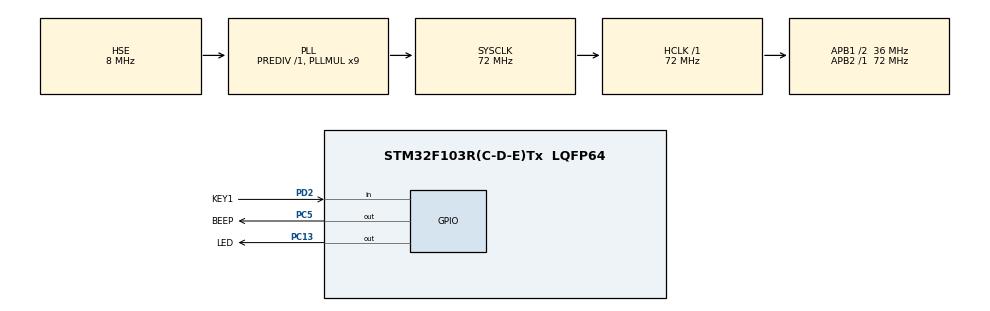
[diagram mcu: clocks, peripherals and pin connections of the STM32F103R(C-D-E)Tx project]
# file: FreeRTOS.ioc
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FREERTOS.Tasks01=defaultTask,0,128,StartDefaultTask,Default,NULL,Dynamic,NULL,NULL;myTask_BEEP,-3,128,StartTask_BEEP,Default,NULL,Dynamic,NULL,NULL;myTask_KEY,-3,128,StartTask_KEY,Default,NULL,Dynamic,NULL,NULL
FREERTOS.configMINIMAL_STACK_SIZE=128
FREERTOS.configUSE_NEWLIB_REENTRANT=1
Mcu.Family=STM32F1
Mcu.Name=STM32F103R(C-D-E)Tx
Mcu.Package=LQFP64
NVIC.PriorityGroup=NVIC_PRIORITYGROUP_4
NVIC.TIM6_IRQn=true\:15\:0\:false\:false\:true\:false\:false\:true\:true
NVIC.TimeBase=TIM6_IRQn
NVIC.TimeBaseIP=TIM6
PA13.Mode=Serial_Wire
PA13.Signal=SYS_JTMS-SWDIO
PA14.Mode=Serial_Wire
PA14.Signal=SYS_JTCK-SWCLK
PC13-TAMPER-RTC.GPIO_Label=LED
PC13-TAMPER-RTC.Signal=GPIO_Output
PC5.GPIO_Label=BEEP
PC5.Signal=GPIO_Output
PD0-OSC_IN.Mode=HSE-External-Oscillator
PD0-OSC_IN.Signal=RCC_OSC_IN
PD1-OSC_OUT.Mode=HSE-External-Oscillator
PD1-OSC_OUT.Signal=RCC_OSC_OUT
PD2.GPIO_Label=KEY1
PD2.GPIO_PuPd=GPIO_PULLUP
PD2.Signal=GPIO_Input
ProjectManager.HeapSize=0x200
ProjectManager.StackSize=0x400
ProjectManager.TargetToolchain=STM32CubeIDE
RCC.AHBFreq_Value=72000000
RCC.APB1CLKDivider=RCC_HCLK_DIV2
RCC.APB1Freq_Value=36000000
RCC.APB1TimFreq_Value=72000000
RCC.APB2Freq_Value=72000000
RCC.APB2TimFreq_Value=72000000
RCC.HCLKFreq_Value=72000000
RCC.PLLMUL=RCC_PLL_MUL9
RCC.PLLSourceVirtual=RCC_PLLSOURCE_HSE
RCC.SYSCLKFreq_VALUE=72000000
RCC.SYSCLKSource=RCC_SYSCLKSOURCE_PLLCLK
RCC.USBFreq_Value=72000000
VP_FREERTOS_VS_CMSIS_V1.Mode=CMSIS_V1
VP_SYS_VS_tim6.Mode=TIM6
board=custom

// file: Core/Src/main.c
/* USER CODE BEGIN Header */
/**
  ******************************************************************************
  * @file           : main.c
  * @brief          : Main program body
  ******************************************************************************
  * @attention
  *
  * Copyright (c) 2022 STMicroelectronics.
  * All rights reserved.
  *
  * This software is licensed under terms that can be found in the LICENSE file
  * in the root directory of this software component.
  * If no LICENSE file comes with this software, it is provided AS-IS.
  *
  ******************************************************************************
  */
/* USER CODE END Header */
#include "main.h"
#include "cmsis_os.h"
#include "gpio.h"

void SystemClock_Config(void);
void MX_FREERTOS_Init(void);

int main(void)
{

  /* MCU Configuration--------------------------------------------------------*/

  /* Reset of all peripherals, Initializes the Flash interface and the Systick. */
  HAL_Init();

  /* Configure the system clock */
  SystemClock_Config();

  /* Initialize all configured peripherals */
  MX_GPIO_Init();

  /* Call init function for freertos objects (in freertos.c) */
  MX_FREERTOS_Init();

  /* Start scheduler */
  osKernelStart();

  /* We should never get here as control is now taken by the scheduler */
  /* Infinite loop */
  while (1)
  {

  }
}

void SystemClock_Config(void)
{
  RCC_OscInitTypeDef RCC_OscInitStruct = {0};
  RCC_ClkInitTypeDef RCC_ClkInitStruct = {0};

  /** Initializes the RCC Oscillators according to the specified parameters
  * in the RCC_OscInitTypeDef structure.
  */
  RCC_OscInitStruct.OscillatorType = RCC_OSCILLATORTYPE_HSE;
  RCC_OscInitStruct.HSEState = RCC_HSE_ON;
  RCC_OscInitStruct.HSEPredivValue = RCC_HSE_PREDIV_DIV1;
  RCC_OscInitStruct.HSIState = RCC_HSI_ON;
  RCC_OscInitStruct.PLL.PLLState = RCC_PLL_ON;
  RCC_OscInitStruct.PLL.PLLSource = RCC_PLLSOURCE_HSE;
  RCC_OscInitStruct.PLL.PLLMUL = RCC_PLL_MUL9;
  if (HAL_RCC_OscConfig(&RCC_OscInitStruct) != HAL_OK)
  {
    Error_Handler();
  }

  /** Initializes the CPU, AHB and APB buses clocks
  */
  RCC_ClkInitStruct.ClockType = RCC_CLOCKTYPE_HCLK|RCC_CLOCKTYPE_SYSCLK
                              |RCC_CLOCKTYPE_PCLK1|RCC_CLOCKTYPE_PCLK2;
  RCC_ClkInitStruct.SYSCLKSource = RCC_SYSCLKSOURCE_PLLCLK;
  RCC_ClkInitStruct.AHBCLKDivider = RCC_SYSCLK_DIV1;
  RCC_ClkInitStruct.APB1CLKDivider = RCC_HCLK_DIV2;
  RCC_ClkInitStruct.APB2CLKDivider = RCC_HCLK_DIV1;

  if (HAL_RCC_ClockConfig(&RCC_ClkInitStruct, FLASH_LATENCY_2) != HAL_OK)
  {
    Error_Handler();
  }
}

void HAL_TIM_PeriodElapsedCallback(TIM_HandleTypeDef *htim)
{
  if (htim->Instance == TIM6) {
    HAL_IncTick();
  }
}

void Error_Handler(void)
{
  __disable_irq();
  while (1)
  {
  }
}

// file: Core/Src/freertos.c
/* USER CODE BEGIN Header */
/**
  ******************************************************************************
  * File Name          : freertos.c
  * Description        : Code for freertos applications
  ******************************************************************************
  * @attention
  *
  * Copyright (c) 2022 STMicroelectronics.
  * All rights reserved.
  *
  * This software is licensed under terms that can be found in the LICENSE file
  * in the root directory of this software component.
  * If no LICENSE file comes with this software, it is provided AS-IS.
  *
  ******************************************************************************
  */
/* USER CODE END Header */

#include "FreeRTOS.h"
#include "task.h"
#include "main.h"
#include "cmsis_os.h"

/* USER CODE BEGIN Includes */
#include "bsp.h"
/* USER CODE END Includes */

/* USER CODE BEGIN Variables */
osThreadId beepTaskHandle;
/* USER CODE END Variables */
osThreadId defaultTaskHandle;
osThreadId myTask_BEEPHandle;
osThreadId myTask_KEYHandle;

void StartDefaultTask(void const * argument);
void StartTask_BEEP(void const * argument);
void StartTask_KEY(void const * argument);

void MX_FREERTOS_Init(void); /* (MISRA C 2004 rule 8.1) */

/* GetIdleTaskMemory prototype (linked to static allocation support) */
void vApplicationGetIdleTaskMemory( StaticTask_t **ppxIdleTaskTCBBuffer, StackType_t **ppxIdleTaskStackBuffer, uint32_t *pulIdleTaskStackSize );

/* USER CODE BEGIN GET_IDLE_TASK_MEMORY */
static StaticTask_t xIdleTaskTCBBuffer;
static StackType_t xIdleStack[configMINIMAL_STACK_SIZE];

void vApplicationGetIdleTaskMemory( StaticTask_t **ppxIdleTaskTCBBuffer, StackType_t **ppxIdleTaskStackBuffer, uint32_t *pulIdleTaskStackSize )
{
  *ppxIdleTaskTCBBuffer = &xIdleTaskTCBBuffer;
  *ppxIdleTaskStackBuffer = &xIdleStack[0];
  *pulIdleTaskStackSize = configMINIMAL_STACK_SIZE;
  /* place for user code */
}
/* USER CODE END GET_IDLE_TASK_MEMORY */

void MX_FREERTOS_Init(void) {

  /* Create the thread(s) */
  /* definition and creation of defaultTask */
  osThreadDef(defaultTask, StartDefaultTask, osPriorityNormal, 0, 128);
  defaultTaskHandle = osThreadCreate(osThread(defaultTask), NULL);

  /* definition and creation of myTask_BEEP */
  osThreadDef(myTask_BEEP, StartTask_BEEP, osPriorityIdle, 0, 128);
  myTask_BEEPHandle = osThreadCreate(osThread(myTask_BEEP), NULL);

  /* definition and creation of myTask_KEY */
  osThreadDef(myTask_KEY, StartTask_KEY, osPriorityIdle, 0, 128);
  myTask_KEYHandle = osThreadCreate(osThread(myTask_KEY), NULL);

}

void StartDefaultTask(void const * argument)
{
  /* USER CODE BEGIN StartDefaultTask */
  /* Infinite loop */
  // for(;;)
  // {
  //   osDelay(1);
  // }
  Task_Entity_LED();
  /* USER CODE END StartDefaultTask */
}

void StartTask_BEEP(void const * argument)
{
  /* USER CODE BEGIN StartTask_BEEP */
  /* Infinite loop */
  // for(;;)
  // {
  //   osDelay(1);
  // }
  Task_Entity_Beep();
  /* USER CODE END StartTask_BEEP */
}

void StartTask_KEY(void const * argument)
{
  /* USER CODE BEGIN StartTask_KEY */
  /* Infinite loop */
  // for(;;)
  // {
  //   osDelay(1);
  // }
  Task_Entity_Key();
  /* USER CODE END StartTask_KEY */
}
